VERSION ""

NS_ :

BS_:

BU_: ECM_HS BCM_HS

BO_ 401 Engine: 8 Vector__XXX
 SG_ ThrottlePosition : 63|8@0+ (0.392157,0) [0|100.000035] "%" Vector__XXX

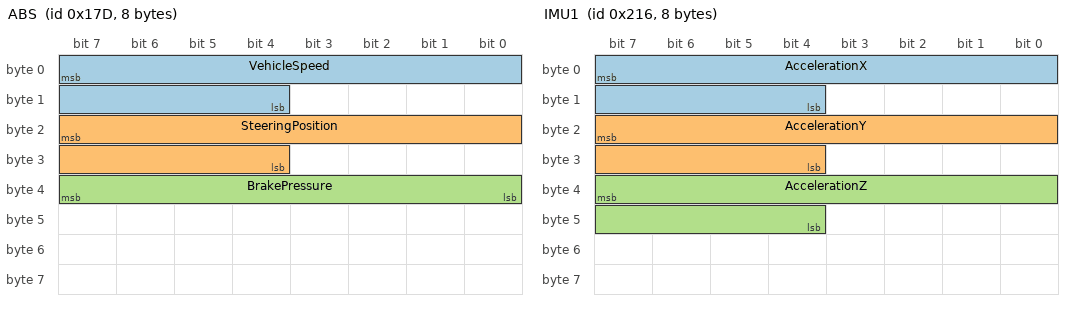
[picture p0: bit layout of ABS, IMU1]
BO_ 381 ABS: 8 Vector__XXX
 SG_ VehicleSpeed : 7|12@0+ (0.0625,0) [0|255.9375] "km / h"  ECM_HS,BCM_HS
 SG_ SteeringPosition : 23|12@0+ (0.0439453125,-90) [-90|89.9560546875] "deg"  ECM_HS,BCM_HS
 SG_ BrakePressure : 39|8@0+ (75,0) [0|19125] "kPa"  ECM_HS,BCM_HS

BO_ 532 Transmission: 8 Vector__XXX
 SG_ Gear : 7|8@0+ (1,-1) [-1|6] ""  ECM_HS,BCM_HS

BO_ 533 Airbag: 8 Vector__XXX
 SG_ CollisionIntensity : 7|12@0+ (24.4140625,0) [0|100000] "N"  ECM_HS,BCM_HS

BO_ 534 IMU1: 8 Vector__XXX
 SG_ AccelerationX : 7|12@0+ (0.48828125,-1000) [-1000|1000] "m/s^2"  ECM_HS,BCM_HS
 SG_ AccelerationY : 23|12@0+ (0.48828125,-1000) [-1000|1000] "m/s^2"  ECM_HS,BCM_HS
 SG_ AccelerationZ : 39|12@0+ (0.48828125,-1000) [-1000|1000] "m/s^2"  ECM_HS,BCM_HS

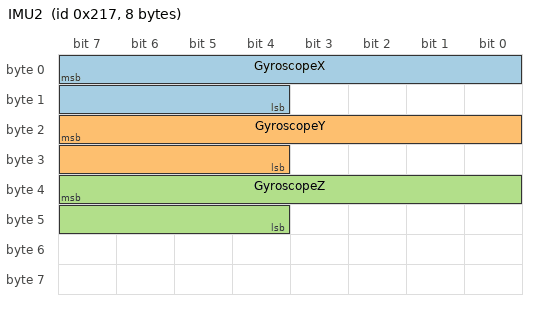
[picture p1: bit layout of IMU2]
BO_ 535 IMU2: 8 Vector__XXX
 SG_ GyroscopeX : 7|12@0+ (0.48828125,-1000) [-1000|1000] "rad/s"  ECM_HS,BCM_HS
 SG_ GyroscopeY : 23|12@0+ (0.48828125,-1000) [-1000|1000] "rad/s"  ECM_HS,BCM_HS
 SG_ GyroscopeZ : 39|12@0+ (0.48828125,-1000) [-1000|1000] "rad/s"  ECM_HS,BCM_HS

BO_ 536 GNSS: 8 Vector__XXX
 SG_ Latitude : 7|32@0+ (0.0000000419095158577,-90) [-90|90] "deg"  ECM_HS,BCM_HS
 SG_ Longitude : 39|32@0+ (0.00000008381903171539,-180) [-180|180] "deg"  ECM_HS,BCM_HS

BO_ 2000 CABIN: 8 Vector__XXX
 SG_ DoorsState : 0|5@0+ (1,0) [0|31] "NOTDEF" Vector__XXX

BO_ 2001 ENV: 8 Vector__XXX
 SG_ AmbientAirTemperature : 0|8@0+ (0.5,-40) [-40|85] "C" Vector__XXX

BA_DEF_ BO_  "GenMsgCycleTime" INT 0 10000;
BA_DEF_DEF_  "GenMsgCycleTime" 0;
BA_ "GenMsgCycleTime" BO_ 401 100;
BA_ "GenMsgCycleTime" BO_ 381 100;
BA_ "GenMsgCycleTime" BO_ 532 100;
BA_ "GenMsgCycleTime" BO_ 533 100;
BA_ "GenMsgCycleTime" BO_ 534 100;
BA_ "GenMsgCycleTime" BO_ 535 100;
BA_ "GenMsgCycleTime" BO_ 536 100;
BA_ "GenMsgCycleTime" BO_ 2000 1000;
BA_ "GenMsgCycleTime" BO_ 2001 1000;
